AUTOSAR XML (schema 00049)
package /RB/PT/PCT_ASW2/SwComponentTypes
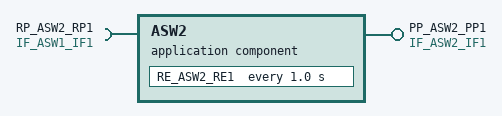
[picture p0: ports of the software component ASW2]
  application sw component type ASW2
    provide port PP_ASW2_PP1: provided-interface=IF_ASW2_IF1
    require port RP_ASW2_RP1: required-interface=IF_ASW1_IF1
    behavior IB_ASW2_IB1: data-type-mapping=[DTMS_ASW2_1, DTMS_ASW2_2]
      timing event TE_ASW2_TE1: start-on-event=RE_ASW2_RE1, period=1.0
      runnable RE_ASW2_RE1: symbol=ASW2_10ms
        data-receive-point-by-values:
          access DRP_ASW2_DRP1: accessed-variable=RP_ASW2_RP1.VDP_ASW1_Var1
        data-send-points:
          access DSP_ASW2_DSP1: accessed-variable=PP_ASW2_PP1.VDP_ASW2_Var1
package /RB/PT/PCT_ASW2/PortInterfaces
  sender receiver interface IF_ASW2_IF1
    data VDP_ASW2_Var1: type=ADT_ASW2_uint32
  sender receiver interface IF_ASW1_IF1
    data VDP_ASW1_Var1: type=ADT_ASW1_uint32
package /RB/PT/PCT_ASW2/ApplicationDataTypes
  app type ADT_ASW2_uint32: category=VALUE, sw-calibration-access=READ-ONLY
package /RB/PT/PCT_ASW2/ImplementationDataTypes
  impl type IDT_ASW2_uint32: implementation-data-type=uint32
package /RB/PT/PCT_ASW2/DataTypeMappingSets
  data type mapping set DTMS_ASW2_1: data-type-map{application-data-type=ADT_ASW2_uint32, implementation-data-type=IDT_ASW2_uint32}
  data type mapping set DTMS_ASW2_2: data-type-map{application-data-type=ADT_ASW1_uint32, implementation-data-type=IDT_ASW1_uint32}
